# CY8C5888LTI_LP097 register map
File version: 0.1
CY8C58LP
Registers are 8-bit, read-write, no defined reset value unless marked. A register's access mark holds for its fields unless they carry their own. Offsets are from the block's base; lines under a group give offsets from that group; [hi:lo] are bit positions; {n}, {i} and the like mark numbered series; 'fields as' and 'values as' point back to an identical list; <NAME> marks a mode.

## Memory map
0x00000000 ADC_A — SAR ADC
0x00000000 ADC_V — SAR ADC
0x00000000 PGA_1
0x00000000 PGA_2
0x00000000 DEBUG_UART — UART
0x00000000 Timer_Speedometer
0x00000000 Timer_RPM
0x00000000 Comp_1
0x00000000 PWM_motor
0x00000000 CAN_1
0x00000000 USBUART_1 — USBFS
0x00000000 VDAC8_1
0x4000646D Status_Reg_1
0x4000647B Control_Reg_motor_reset
0x40006567 Status_Reg_OverCurrent

## ADC_A — SAR ADC
Base 0x00000000
0x40004614 SAR_TR0 — SAR trim register
{0x40005900+i} SAR_CSR{i} (i=0..6) — SAR status and control register {i}
0x40005B20 SAR_SW0 — SAR Analog Routing Register 0
{0x40005B20+i} SAR_SW{i} (i=2..4) — SAR Analog Routing Register {i}
0x40005B26 SAR_SW6 — SAR Analog Routing Register 6
0x40005B27 SAR_CLK — SAR Clock Selection Register
0x40005BA0 SAR_WRK 16-bit — SAR working register

## ADC_V — SAR ADC
Base 0x00000000
0x40004616 SAR_TR0 — SAR trim register
{0x40005908+i} SAR_CSR{i} (i=0..6) — SAR status and control register {i}
0x40005B28 SAR_SW0 — SAR Analog Routing Register 0
{0x40005B28+i} SAR_SW{i} (i=2..4) — SAR Analog Routing Register {i}
0x40005B2E SAR_SW6 — SAR Analog Routing Register 6
0x40005B2F SAR_CLK — SAR Clock Selection Register
0x40005BA2 SAR_WRK 16-bit — SAR working register

## Status_Reg_1
Base 0x4000646D
0x00 Status_Reg_1_STATUS_REG
0x20 Status_Reg_1_MASK_REG
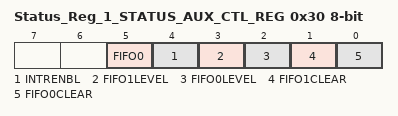
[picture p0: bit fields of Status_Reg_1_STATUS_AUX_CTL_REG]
0x30 Status_Reg_1_STATUS_AUX_CTL_REG
  [5] FIFO0 — FIFO0 clear
    1=ENABLED (Enable counter); 0=DISABLED (Disable counter)
  [4] INTRENBL — Enables or disables the Interrupt
    1=ENABLED (Interrupt enabled); 0=DISABLED (Interrupt disabled)
  [3] FIFO1LEVEL — FIFO level
    1=ENABLED (FIFO LVL: input mode: FIFO at least 1/2 empty; output mode: FIFO at least 1/2 full); 0=DISABLED (FIFO LVL: input mode: FIFO not full; output mode: FIFO not empty)
  [2] FIFO0LEVEL — FIFO level
    values as FIFO1LEVEL
  [1] FIFO1CLEAR — FIFO clear
    1=ENABLED (Clear FIFO state); 0=DISABLED (Normal FIFO operation)
  [0] FIFO0CLEAR — FIFO clear
    values as FIFO1CLEAR

## Status_Reg_OverCurrent
Base 0x40006567
Registers as Status_Reg_1 (with Status_Reg_1 read as Status_Reg_OverCurrent).

## DEBUG_UART — UART
Base 0x00000000
0x40006546 TX_DEBUG_UART_TX_DATA — TX Data Register
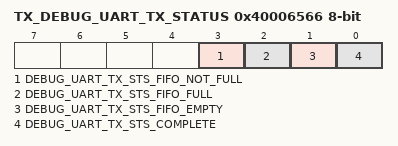
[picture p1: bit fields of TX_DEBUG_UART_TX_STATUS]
0x40006566 TX_DEBUG_UART_TX_STATUS — TX status register
  [3] DEBUG_UART_TX_STS_FIFO_NOT_FULL ro, [2] DEBUG_UART_TX_STS_FIFO_FULL ro, [1] DEBUG_UART_TX_STS_FIFO_EMPTY ro, [0] DEBUG_UART_TX_STS_COMPLETE ro

## Timer_Speedometer
Base 0x00000000
0x40006402 Timer_Speedometer_COUNTER 16-bit — UDB.A0 - Current Down Counter Value
0x40006422 Timer_Speedometer_PERIOD 16-bit — UDB.D0 - Assigned Period
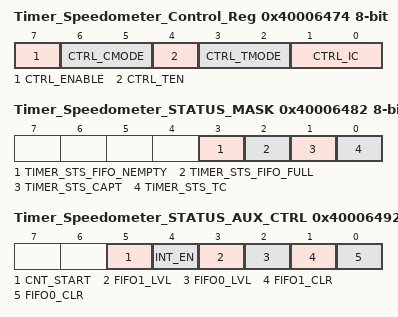
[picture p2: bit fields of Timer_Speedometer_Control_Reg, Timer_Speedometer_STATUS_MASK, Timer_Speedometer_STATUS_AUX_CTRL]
0x40006474 Timer_Speedometer_Control_Reg — UDB Control Register - Assigned Control Register Value
  [7] CTRL_ENABLE — Enable the Timer
  [6:5] CTRL_CMODE — Capture Mode
  [4] CTRL_TEN — Trigger Enable Bit
  [3:2] CTRL_TMODE — Trigger Mode
  [1:0] CTRL_IC — Interrupt Count
0x40006482 Timer_Speedometer_STATUS_MASK — UDB Status bits Interrupt Mask Enable Register
  [3] TIMER_STS_FIFO_NEMPTY ro — FIFO Empty status
  [2] TIMER_STS_FIFO_FULL ro — FIFO Full Status
  [1] TIMER_STS_CAPT ro — Enables the Interrupt on Capture
  [0] TIMER_STS_TC ro — Enables the Interrupt on TC
0x40006492 Timer_Speedometer_STATUS_AUX_CTRL — UDB Auxilliary Control Register
  [5] CNT_START — FIFO0 clear
    0=E_CNT_START0 (Disable counter); 1=E_CNT_START1 (Enable counter)
  [4] INT_EN
    0=E_INT_EN0 (Interrupt disabled); 1=E_INT_EN1 (Interrupt enabled)
  [3] FIFO1_LVL — FIFO level
    0=E_FIFO_LVL_0 (FIFO LVL: input mode: FIFO not full; output mode: FIFO not empty); 1=E_FIFO_LVL_1 (FIFO LVL: input mode: FIFO at least 1/2 empty; output mode: FIFO at least 1/2 full)
  [2] FIFO0_LVL — FIFO level
    values as FIFO1_LVL
  [1] FIFO1_CLR — FIFO1 clear
    0=E_FIFO_CLR_0 (Normal FIFO operation); 1=E_FIFO_CLR_1 (Clear FIFO state)
  [0] FIFO0_CLR — FIFO0 clear
    values as FIFO1_CLR
